# DMASS_BCDMA_0_DMASS_BCDMA_0_BCDMA_CHANRT_48800000h register map
Vendor: Texas Instruments
Peripheral module from a debugger description file (folder am62L).
Registers are 32-bit, read-write, reset 0x0 unless marked. A register's access mark holds for its fields unless they carry their own. Offsets are as the file gives them; lines under a group give offsets from that group; [hi:lo] are bit positions; {n}, {i} and the like mark numbered series; 'fields as' and 'values as' point back to an identical list; <NAME> marks a mode.

## DMASS_BCDMA_0_BCDMA_CHANRT
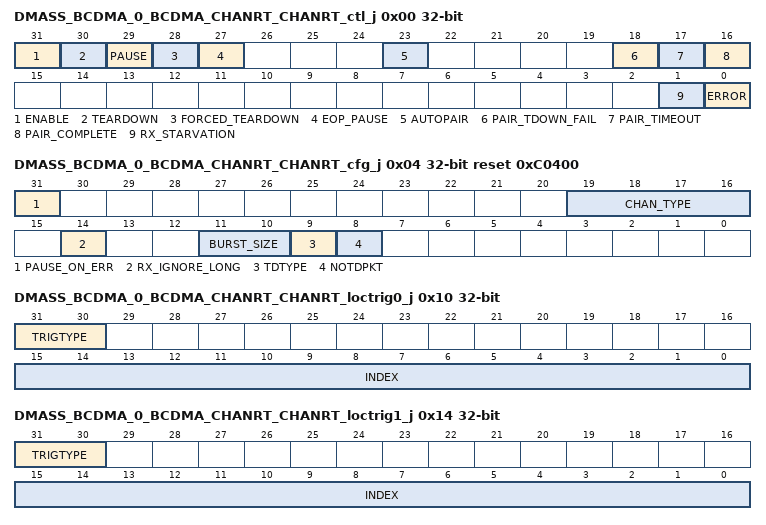
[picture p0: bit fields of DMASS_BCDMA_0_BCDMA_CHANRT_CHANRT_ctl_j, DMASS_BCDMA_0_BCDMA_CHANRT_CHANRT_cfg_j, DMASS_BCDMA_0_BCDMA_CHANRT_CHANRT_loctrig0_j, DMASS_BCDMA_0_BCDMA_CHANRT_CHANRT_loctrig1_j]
0x00 DMASS_BCDMA_0_BCDMA_CHANRT_CHANRT_ctl_j access not given — The Channel Realtime Control Register contains real-time control and status information for the DMA channel. The fields in this register can safely be changed while the channel is in operation.
  [31] ENABLE rw — This field enables or disables the channel. Disabling a channel halts operation on the channel after the current block transfer is completed. Disabling a channel in the middle of a packet transfer may result in underflow conditions in the attached application block and data loss. When a channel is disabled, the implementation may choose to reset all state for the channel. The pause bit should be asserted instead of clearing enable directly if the intent is to temporarily pause the channel. This field is encoded as follows: 0 = channel is disabled 1 = channel is enabled This field will be cleared by HW after a teardown is requested to indicate that the channel teardown is complete. Reset Source: rst_mod_g_rst_n
  [30] TEARDOWN rw — Setting this bit will request the channel to be torn down. This field will remain set after a channel teardown is complete. Reset Source: rst_mod_g_rst_n
  [29] PAUSE rw — Setting this bit will cause the channel to pause processing immediately. Reset Source: rst_mod_g_rst_n
  [28] FORCED_TEARDOWN rw — Setting this bit will cause the channel to stop waiting on trigger events and any required data. When this bit is set, the implementation may choose to bypass data transfers and event generation. This bit is provided if the normal teardown is not able to work. It is intended to flush the channel to recover any descriptor or TR references which are currently being held by the BCDMA even if the external resource is no longer functioning. Use of this bit is considered a 'catastrophic' condition and it is assumed that SW will need to perform some re-initialization in the system to re-align events, data buffers, etc. If auto pairing is not used the credits between the paired endpoints MUST be reset after a force teardown. This bit is typcially set if teardown bit did not complete clearing the enable. If the channel is already locked up the forced teardown can be set without also setting teardown. This field will remain set after a channel teardown is complete. Reset Source: rst_mod_g_rst_n
  [27] EOP_PAUSE rw — Setting this bit will cause the channel to pause after the current TR has completed. This ensures all credits will be returned and connected endpoints can be reset or powered down and the DMA can reasume once the endpoint is started back up. This register will set the pause pause bit in this register when the End of Packet condition has been reached. Software can poll the pause bit to see when it is safe to reset the endpoint attached to the channel that is being paused on the end of the packet. Reset Source: rst_mod_g_rst_n
  [23] AUTOPAIR rw — Setting this bit will cause the channel to pair to the remote endpoint and attempt to set the channel up. The pairing can be checked by reading paired status bit. Reset Source: rst_mod_g_rst_n
  [18] PAIR_TDOWN_FAIL — This bit is set when teardown is set and pair complete is set and the teardown sequence did not complete successfully. Reset Source: rst_mod_g_rst_n (access R/W1TC)
  [17] PAIR_TIMEOUT — This bit is set when the pair bit has been set and the pairing to the endpoint was not able to complete sucessfully. If this is set it could mean that the endpoint was enabled by another DMA or that the endpoint did not respond to the pairing requests. Clearing this bit will attempt the autopair teardown sequence again if the pair complete bit remains set. Reset Source: rst_mod_g_rst_n (access R/W1TC)
  [16] PAIR_COMPLETE — This bit is set when the autopair bit has been set and the endpoint was successfully connected to the DMA channel. This bit will remain set until the teardown or forced teardown or enable in this register is cleared Reset Source: rst_mod_g_rst_n (access R/W0TC)
  [1] RX_STARVATION ro — his bit is set if the port receives a packet and the ring is empty. The bit clears when the doorbell is written with a positive value. This is only valid for an RX channel. Reset Source: rst_mod_g_rst_n
  [0] ERROR — This bit will be set anytime an error has occurred on the channel. This bit is cleared by writing back a 0. Reset Source: rst_mod_g_rst_n (access R/W0TC)
0x04 DMASS_BCDMA_0_BCDMA_CHANRT_CHANRT_cfg_j access not given reset 0xC0400 — The Channel Configuration Register is used to initialize static mode settings for the DMA channel. This register may only be written when the channel is disabled (enable in realtime control reg is 0). This register is only visible if the alias cfg bit is set in the Channel Resource Register.
  [31] PAUSE_ON_ERR rw — Pause On Error: this field controls what the channel will do if an error or exception occurs during a data transfer. This field is encoded as follows: 0 = Channel will report error and continue current work and move on when finished 1 = Channel will pause and wait for SW to investigate and un-pause the channel. Reset Source: rst_mod_g_rst_n
  [19:16] CHAN_TYPE — Channel Type: this field controls and / or indicates the functional channel type for this channel and the work passing mechanism that the channel uses for communicating with the Host. 0 Channel is not a valid channel for this DMA10 Channel performs Third Party DMA transfers from memory to PSI-L peripherals using pass by reference rings.12 Pass by reference block copy (access R/NA)
  [14] RX_IGNORE_LONG rw — This field controls whether or not long packets will be treated as exceptions or ignored for the channel. This field is only used when the channel is in split UTC mode. The values are encoded as follows: 0 = Long packets are treated as exceptions and handled appropriately. 1 = Long packets are ignored and the next TR will be fetched even if the current TR is marked or interpreted as EOP. This bit is only valid for RX channel. Reset Source: rst_mod_g_rst_n
  [11:10] BURST_SIZE rw — Specifies the nominal burst size and alignment for data transfers on this channel. The optimal burst size setting is to maximize utilization of the channel FIFOs. Reset Source: rst_mod_g_rst_n
  [9] TDTYPE rw — Specifies whether or not the channel should immediately return a teardown completion response to the default completion queue or wait until a status message is returned from the remote PSI-L paired peripheral. 0 = return immediately once all traffic is complete in BCDMA. 1 = wait until remote peer sends back a completion message. It is assumed that if the TX peripheral sends a tdown completion message it also sends EOP completion messages. Setting this bit enables delaying of TX completion events until the EOP completion message is received as well. This field is only valid if the channel is for a TX peripheral otherwise it is reserved Reset Source: rst_mod_g_rst_n
  [8] NOTDPKT rw — Specifies whether or not the channel should suppress sending the single data phase teardown packet when teardown is complete. 0 = TD packet is sent 1 = Suppress sending TD packet. This field is only valid for a TX peripherial otherwise it is reserved Reset Source: rst_mod_g_rst_n
0x08 DMASS_BCDMA_0_BCDMA_CHANRT_CHANRT_swtrig_j access not given — The Software Trigger Register provides a mechanism by which software can directly trigger the channel in a secure way. This register is only used when the tx_chan_type is configured as a Third Party DMA channel. This register has no function when the channel is configured for packet mode transfers. A write to this register will cause an event to be sent to this channel.
  [0] TRIGGER — writing this bit with a value of 1 will cause the trigger event to be sent to this channel Reset Source: rst_mod_g_rst_n (access NA/W)
0x10 DMASS_BCDMA_0_BCDMA_CHANRT_CHANRT_loctrig0_j — This register selects which local trigger will increment the counter for the trigger0 specified in the TR.
  [31:30] TRIGTYPE — Selects if the trigger is coming from an internall channel event or one of the two external edge detect evets. 0 disabled1 channel event2 external signal3 timer manager event
  [15:0] INDEX — Selects the index to use for the trigger. For a channel trigger type it will be the TR event for the channel number specified. For an external signal or timer signal it will select the bit of the global interfaces that come into the DMA as specified in the SOC specification Reset Source: rst_mod_g_rst_n
0x14 DMASS_BCDMA_0_BCDMA_CHANRT_CHANRT_loctrig1_j — This register selects which local trigger will increment the counter for the trigger1 specified in the TR.
  [31:30] TRIGTYPE — Selects if the trigger is coming from an internall channel event or one of the two external edge detect events. 0 disabled1 channel event2 timer manager event3 external signal
  [15:0] INDEX — Selects the index to use for the trigger. For a channel trigger type it will be the TR event for the channel number specified. For an external signal or timer signal it will select the bit of the global interfaces that come into the DMA as specified in the SOC specification Reset Source: rst_mod_g_rst_n
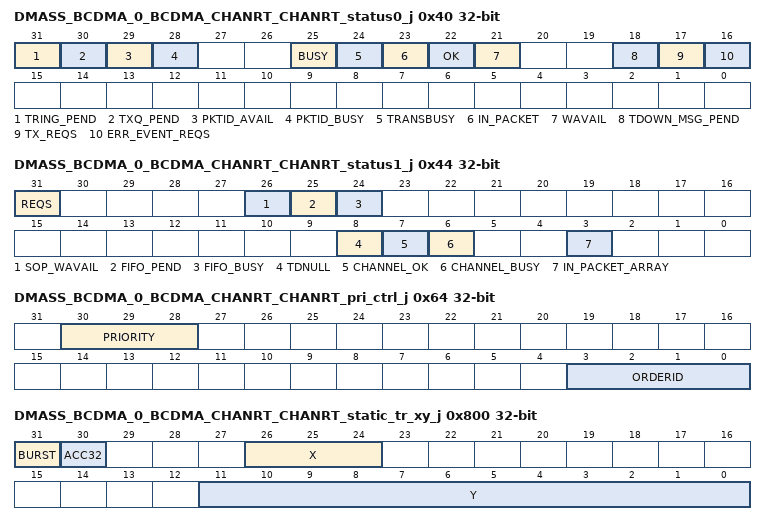
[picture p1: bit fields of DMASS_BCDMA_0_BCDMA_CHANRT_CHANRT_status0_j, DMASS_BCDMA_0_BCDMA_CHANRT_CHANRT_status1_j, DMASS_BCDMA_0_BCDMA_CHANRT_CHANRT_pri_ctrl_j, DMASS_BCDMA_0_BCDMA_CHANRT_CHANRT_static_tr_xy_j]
0x40 DMASS_BCDMA_0_BCDMA_CHANRT_CHANRT_status0_j ro — The Status Register provides a read only view of channel status bits.
  [31] TRING_PEND — The channel ring has a descriptor Reset Source: rst_mod_g_rst_n
  [30] TXQ_PEND — The channel fifo is available Reset Source: rst_mod_g_rst_n
  [29] PKTID_AVAIL — The channel has an available packet id Reset Source: rst_mod_g_rst_n
  [28] PKTID_BUSY — There is an outstanding pktid for the channel Reset Source: rst_mod_g_rst_n
  [25] BUSY — The channel is busy Reset Source: rst_mod_g_rst_n
  [24] TRANSBUSY — The channel has an outstanding transaction Reset Source: rst_mod_g_rst_n
  [23] IN_PACKET — The channel is currently in a packet Reset Source: rst_mod_g_rst_n
  [22] OK — The channel is ready to be scheduled Reset Source: rst_mod_g_rst_n
  [21] WAVAIL — The fifo for the channel has space to place a burst size entry Reset Source: rst_mod_g_rst_n
  [18] TDOWN_MSG_PEND — A teardown message is pending Reset Source: rst_mod_g_rst_n
  [17] TX_REQS — The channel is sending a schedule request Reset Source: rst_mod_g_rst_n
  [16] ERR_EVENT_REQS — The channel is trying to schedule an error event Reset Source: rst_mod_g_rst_n
0x44 DMASS_BCDMA_0_BCDMA_CHANRT_CHANRT_status1_j ro — The Status Register provides a read only view of channel status bits.
  [31] REQS — The channel is sending a schedule request Reset Source: rst_mod_g_rst_n
  [26] SOP_WAVAIL — The FIFO has space for the start of a packet Reset Source: rst_mod_g_rst_n
  [25] FIFO_PEND — The FIFO has enough data for a burst Reset Source: rst_mod_g_rst_n
  [24] FIFO_BUSY — The fifo has data Reset Source: rst_mod_g_rst_n
  [8] TDNULL — Channel is trying to teardown and has met conditions Reset Source: rst_mod_g_rst_n
  [7] CHANNEL_OK — Channel is trying to schedule a transaction Reset Source: rst_mod_g_rst_n
  [6] CHANNEL_BUSY — The channel is active Reset Source: rst_mod_g_rst_n
  [3] IN_PACKET_ARRAY — The channel is in a packet Reset Source: rst_mod_g_rst_n
0x64 DMASS_BCDMA_0_BCDMA_CHANRT_CHANRT_pri_ctrl_j — The priority control register is used to control the priority of the transactions which the DMA generates on it's master interface. This register is only visible if the alias cfg bit is set in the Channel Resource Register.
  [30:28] PRIORITY — Priority: This field contains the 3-bit value which will be output on the mem*_cpriority and mem_cepriority outputs during all transactions for this channel. Reset Source: rst_mod_g_rst_n
  [3:0] ORDERID — Order ID: This field contains the 4-bit value which will be output on the mem*_corderid output during all transactions for this channel. Reset Source: rst_mod_g_rst_n
0x68 DMASS_BCDMA_0_BCDMA_CHANRT_CHANRT_thread_j — The thread ID mapping register is used to pair the DMA channel to a specific destination thread. All traffic generated from this channel will be sent with a thread_id on the PSI-L interface with the value from this register. This register is only valid if the channel is a TX or RX peripheral channel. This register is only visible if the alias cfg bit is set in the Channel Resource Register.
  [15:0] THREAD_ID — This field contains the (up-to) 16-bit value which will be output on the strm_o_thread_id output during all transactions for this channel. Reset Source: rst_mod_g_rst_n
0x70 DMASS_BCDMA_0_BCDMA_CHANRT_CHANRT_fifo_depth_j reset 0xC0 — The fifo depth register is used to specify how many FIFO data phases deep the Tx per channel FIFO will be for the channel. While the maximum depth of the Tx FIFO is set at design time, the FIFO depth can be artificially reduced in order to control the maximum latency which can be introduced due to buffering effects. This register only exists if this channel is a TX peripheral channel otherwise it is reserved.
  [7:0] FDEPTH — This field contains the number of Tx FIFO bytes which will be allowed to be stored for the channel. The minimum value is equal to the PSI-L interface data path width (tstrm_wdth), the maximum value varies by channel class (ultra-high capacity/high capacity/normal capacity) and is equal to the tubuf_size/thbuf_size/tbuf_size parameter respectively multiplied by the PSI-L data path width (tstrm_wdth). The fdepth must always be an integer multiple of 16. The reset value of this register varies by channel but will be equal to the value for the specific channel. Do NOT modify if the channel is going to be used in loopback and send mode for XLCDMA Reset Source: rst_mod_g_rst_n
0x78 DMASS_BCDMA_0_BCDMA_CHANRT_CHANRT_tst_sched_j — The Channel N Static Scheduler Configuration Register contains static configuration information which affects the conditions under which each channel will be given an opportunity to use the DMA unit(s). This register is only visible if the alias cfg bit is set in the Channel Resource Register. The fields in this register are as follows:
  [1:0] PRIORITY — These bits select which scheduling bin the channel will be placed in for bandwidth allocation of the Tx/Rx DMA units. This field is encoded as follows: 0 = High priority 1 = Medium - high priority 2 = Medium - low priority 3 = Low priority Arbitration between bins is performed in a strict priority fashion. High priority channels will always be serviced first. If no high priority channels are requesting then all medium-high priority channels will be serviced next. If no high priority or medium-high priority channels are requesting then all medium-low priority channels will be serviced next. When no other channels are requesting, the low priority channels will be serviced. All channels within a given bin are serviced in a round robin order. Only channels which are enabled and which have sufficient free space in their Per Channel FIFO will be included in the round robin arbitration. Reset Source: rst_mod_g_rst_n
0x80 DMASS_BCDMA_0_BCDMA_CHANRT_CHANRT_stdata_j_k access not given — The State Data Registers contain the current working state of the Tx DMA channel. These registers are provided so that the Host can determine the potential cause of an error or exception condition which was reported by the channel. These registers should not be accessed without reason while the DMA is operating as accesses will cause performance to decrease as these MMRs are just providing a window into the actual state RAM
  [31:0] STATE_INFO — See Tx state mapping table Reset Source: rst_mod_g_rst_n (access R/NA)
0x400 DMASS_BCDMA_0_BCDMA_CHANRT_CHANRT_pcnt_j access not given — The statistics registers are supplied to give software applications operational progress status for the channel.
  [31:0] PCNT — Current completed packet count for the channel. Reset Source: rst_mod_g_rst_n (access R/WTD)
0x408 DMASS_BCDMA_0_BCDMA_CHANRT_CHANRT_bcnt_j access not given — The statistics registers are supplied to give software applications operational progress status for the channel.
  [31:0] BCNT — Current completed payload byte count for the channel. Reset Source: rst_mod_g_rst_n (access R/WTD)
0x410 DMASS_BCDMA_0_BCDMA_CHANRT_CHANRT_sbcnt_j access not given — The statistics registers are supplied to give software applications operational progress status for the channel.
  [31:0] SBCNT — Current started byte count for the channel. Reset Source: rst_mod_g_rst_n (access R/WTD)
0x800 DMASS_BCDMA_0_BCDMA_CHANRT_CHANRT_static_tr_xy_j — After reset, all channels in the PDMA will be idle and waiting for work to be assigned to them. In order to initiate DMA operation on a peripheral, the Host will set up the static TR for the peripheral side of the channel. The format of the TR is identical for each DMA mode, consisting of an X, Y, and Z parameter, but the field interpretation varies based on the peripheral. This registers holds the X and Y parameters
  [31] BURST — When set, enables VBUSP burst mode on this channel. See the XY burst description for more information. Reset Source: rst_mod_g_rst_n
  [30] ACC32 — When set, enables 32-bit access mode. On a 32-bit PDMA, all accesses will have XCNT=4 to support legacy IP that is not fully VBUSP compliant. This bit is ignored if the Peripheral VBUSP port is not 32 bits wide. Reset Source: rst_mod_g_rst_n
  [26:24] X — This field specifies how much data is transferred in each write which is performed by the DMA. This field is encoded as follows: 0 = 8 bits, 1 = 16 bits, 2 = 24 bits, 3 = 32 bits, 4 = 64 bits, and 5-7 = RESERVED Reset Source: rst_mod_g_rst_n
  [11:0] Y — This field holds the current Y count. In X-Y FIFO mode, this is the number of X sized samples yet to be read from the peripheral for the DMA event being serviced. In MCAN mode, this field holds the next read offset to use when read to the CAN RX buffer. Reset Source: rst_mod_g_rst_n
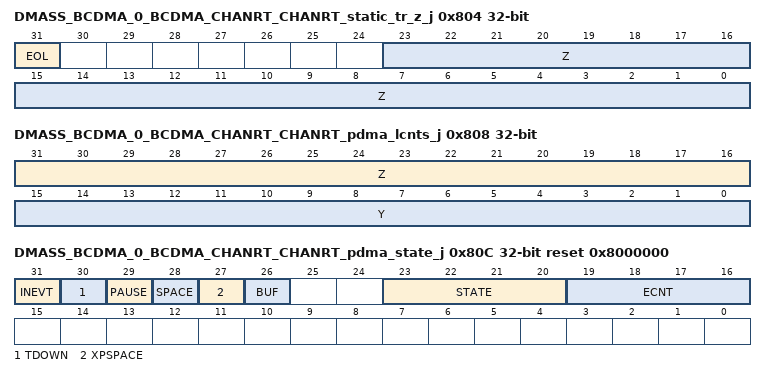
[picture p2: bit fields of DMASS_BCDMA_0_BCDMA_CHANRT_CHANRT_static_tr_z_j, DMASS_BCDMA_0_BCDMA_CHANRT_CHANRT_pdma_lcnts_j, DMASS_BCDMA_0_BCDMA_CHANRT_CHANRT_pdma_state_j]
0x804 DMASS_BCDMA_0_BCDMA_CHANRT_CHANRT_static_tr_z_j — After reset, all channels in the PDMA will be idle and waiting for work to be assigned to them. In order to initiate DMA operation on a peripheral, the Host will set up the static TR for the peripheral side of the channel. The format of the TR is identical for each DMA mode, consisting of an X, Y, and Z parameter, but the field interpretation varies based on the peripheral this register holds the Z parameters. This register is only on RX channels that send data from the PDMA to the Paired DMA
  [31] EOL — Normally, when the Z count of FIFO operations has been reached, the Peripheral will close the packet with an end of packet indication going to either the next packet or TR. When this flag is set, the peripheral will instead trigger an end of line at the completion of Z which will make the receiving TR increment the ICNT1 but remain in the same TR. Reset Source: rst_mod_g_rst_n
  [23:0] Z — This field specifies how many full FIFO operations comprise a complete packet. When the count has been reached, the Peripheral will close the packet with an End of Packet indication that will cause the DMA to end the current packet or TR. If this parameter is set to NULL, then no packet delineation is supplied by the Peripheral and all framing is controlled via the paired DMA TR. Reset Source: rst_mod_g_rst_n
0x808 DMASS_BCDMA_0_BCDMA_CHANRT_CHANRT_pdma_lcnts_j access not given — This register gives counts of the loop counts in the PDMA
  [31:16] Z — These the current lower bits of Z for an RX channel Reset Source: rst_mod_g_rst_n (access R/NA)
  [15:0] Y — This the current count of Y Reset Source: rst_mod_g_rst_n (access R/NA)
0x80C DMASS_BCDMA_0_BCDMA_CHANRT_CHANRT_pdma_state_j access not given reset 0x8000000 — This register gives information to the DMA engine attached to the peripheral
  [31] INEVT — When set, the PDMA is in the middle of processing a FIFO event. Reset Source: rst_mod_g_rst_n (access R/NA)
  [30] TDOWN — When set, the PDMA is processing a teardown operation. This bit is set simultaneously with the teardown bit in the source (RX) RT enable register. This bit will clear when the teardown is complete, regardless as to if the teardown bit in the pairing register is cleared or not. The teardown will propagate to the paired DMA and its full completion status can be checked there. Reset Source: rst_mod_g_rst_n (access R/NA)
  [29] PAUSE — When set, the PDMA is stopped in a paused state. This bit will clear if the channel is un-paused or disabled. Reset Source: rst_mod_g_rst_n (access R/NA)
  [28] SPACE — When set, there is a non-zero amount of internal FIFO space available to hold new read data. Reset Source: rst_mod_g_rst_n (access R/NA)
  [27] XPSPACE — When set, there is a enough internal FIFO space available to start servicing a peripheral DMA event. Reset Source: rst_mod_g_rst_n (access R/NA)
  [26] BUF — This is the current RX buffer (0/1) for the current MCAN receive operation. Reset Source: rst_mod_g_rst_n (access R/NA)
  [23:20] STATE — This code reflects the current state of the PDMA channel, and is specific to the current implementation. Reset Source: rst_mod_g_rst_n (access R/NA)
  [19:16] ECNT — This field holds the number of backlogged DMA events yet to be serviced. Reset Source: rst_mod_g_rst_n (access R/NA)
0x810 DMASS_BCDMA_0_BCDMA_CHANRT_CHANRT_periph_bcnt_j — This is a counter for the number of bytes the peripheral has transferred
  [30:0] BYTES — This register contains the number of bytes that have been accessed from the VBUSP mapped peripheral. The register is write to decrement, so running counts can be tracked by reading register and then writing back the value that was read. It will wrap on overflow. It will reset to zero on a channel reset. Reset Source: rst_mod_g_rst_n
0x824 DMASS_BCDMA_0_BCDMA_CHANRT_CHANRT_fifo_sel_j — This register is used to select which of the multiple FIFOs the PDMA should use. This register is only present if the PDMA is a XYMF type otherwise it is reserved
  [3:0] FIFO — This is the FIFO for the PDMA that the channel is using Reset Source: rst_mod_g_rst_n
0x83C DMASS_BCDMA_0_BCDMA_CHANRT_CHANRT_periph_fzcnt_j — This is the full Z count for the perphiral
  [31:0] CURR — This field holds the full width value of the current Z count. In X-Y FIFO mode, this field holds the 1 based FIFO count of the FIFO being currently read, or the number of FIFO completions when the current operation completes. In MCAN mode, this field holds the zero based buffer index of the buffer currently being read, or the number of previously completed buffers. This register is only valid for an RX channel that sends data from the PDMA. Reset Source: rst_mod_g_rst_n
